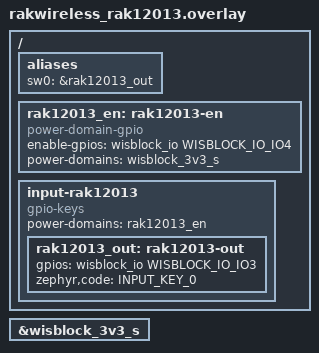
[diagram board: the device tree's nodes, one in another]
/*
 * SPDX-FileCopyrightText: Copyright (c) 2026 RAKwireless Technology Limited
 * SPDX-License-Identifier: Apache-2.0
 *
 * RAK12013 is an RCWL-9196 Doppler radar on the WisBlock IO slot.
 * Connector pin 31 (OUT) is IO3 and is high while motion is detected.
 * Connector pin 32 (EN) is IO4 and reaches the radar ENABLE pin, which
 * the module pulls up to the radar's own supply, so the radar runs
 * unless IO4 is driven low. Connector pin 6 is 3V3_S, the only supply
 * the module has, and WisBlock IO2 switches it.
 */

#include <zephyr/dt-bindings/gpio/gpio.h>
#include <zephyr/dt-bindings/gpio/wisblock-io-slot.h>
#include <zephyr/dt-bindings/input/input-event-codes.h>

&wisblock_3v3_s {
	status = "okay";
};

/ {
	aliases {
		sw0 = &rak12013_out;
	};

	rak12013_en: rak12013-en {
		compatible = "power-domain-gpio";
		enable-gpios = <&wisblock_io WISBLOCK_IO_IO4 GPIO_ACTIVE_HIGH>;
		power-domains = <&wisblock_3v3_s>;
		#power-domain-cells = <0>;
	};

	input-rak12013 {
		compatible = "gpio-keys";
		power-domains = <&rak12013_en>;

		rak12013_out: rak12013-out {
			gpios = <&wisblock_io WISBLOCK_IO_IO3 GPIO_ACTIVE_HIGH>;
			zephyr,code = <INPUT_KEY_0>;
		};
	};
};
